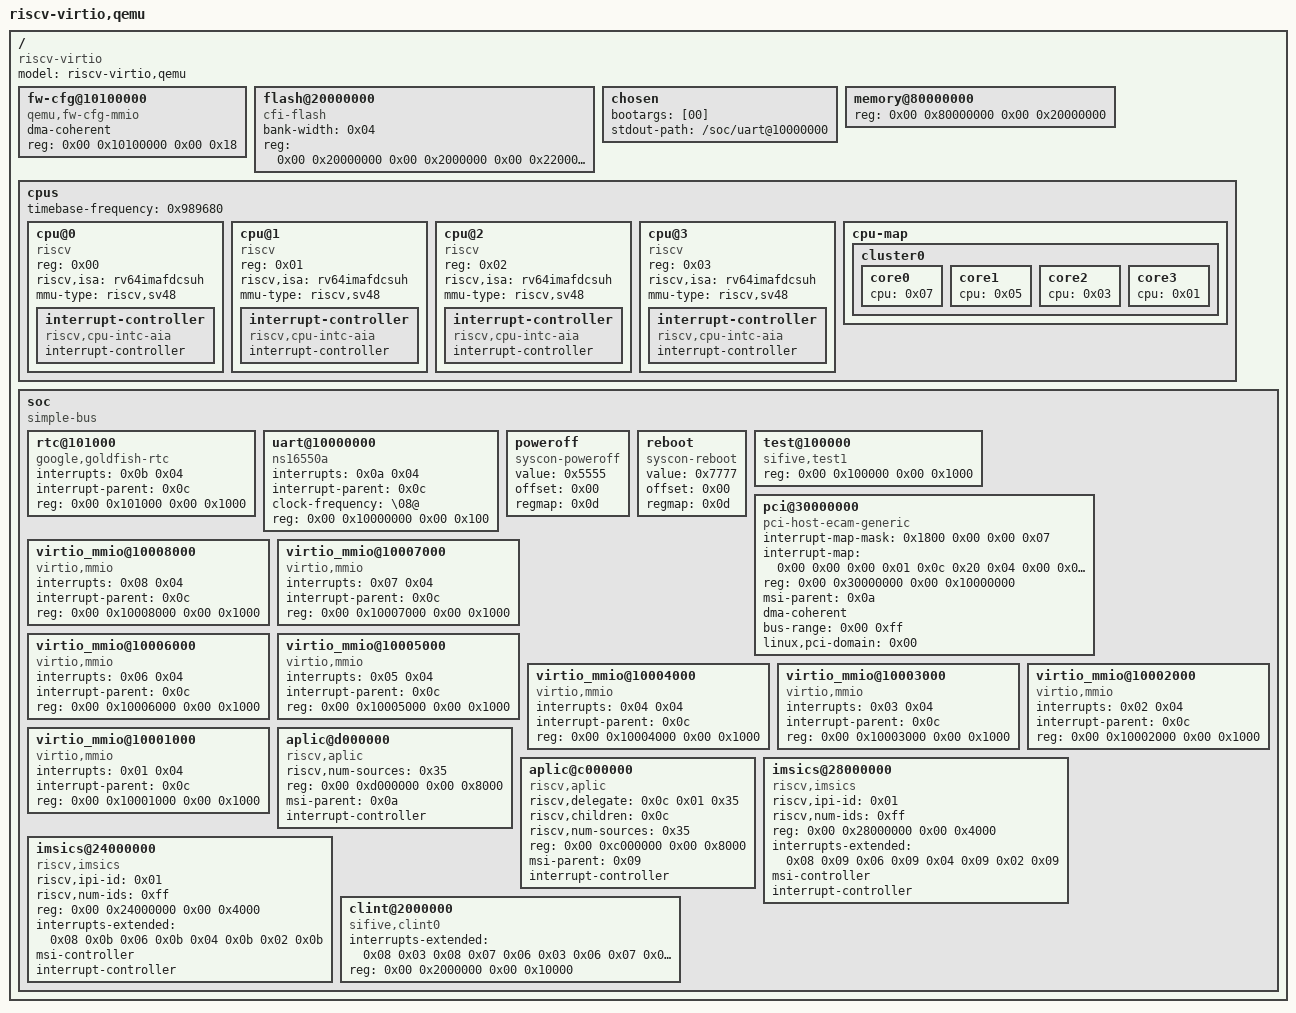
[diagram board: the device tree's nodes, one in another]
/dts-v1/;

/ {
	#address-cells = <0x02>;
	#size-cells = <0x02>;
	compatible = "riscv-virtio";
	model = "riscv-virtio,qemu";

	fw-cfg@10100000 {
		dma-coherent;
		reg = <0x00 0x10100000 0x00 0x18>;
		compatible = "qemu,fw-cfg-mmio";
	};

	flash@20000000 {
		bank-width = <0x04>;
		reg = <0x00 0x20000000 0x00 0x2000000 0x00 0x22000000 0x00 0x2000000>;
		compatible = "cfi-flash";
	};

	chosen {
		bootargs = [00];
		stdout-path = "/soc/uart@10000000";
	};

	memory@80000000 {
		device_type = "memory";
		reg = <0x00 0x80000000 0x00 0x20000000>;
	};

	cpus {
		#address-cells = <0x01>;
		#size-cells = <0x00>;
		timebase-frequency = <0x989680>;

		cpu@0 {
			phandle = <0x07>;
			device_type = "cpu";
			reg = <0x00>;
			status = "okay";
			compatible = "riscv";
			riscv,isa = "rv64imafdcsuh";
			mmu-type = "riscv,sv48";

			interrupt-controller {
				#interrupt-cells = <0x01>;
				interrupt-controller;
				compatible = "riscv,cpu-intc-aia\0riscv,cpu-intc";
				phandle = <0x08>;
			};
		};

		cpu@1 {
			phandle = <0x05>;
			device_type = "cpu";
			reg = <0x01>;
			status = "okay";
			compatible = "riscv";
			riscv,isa = "rv64imafdcsuh";
			mmu-type = "riscv,sv48";

			interrupt-controller {
				#interrupt-cells = <0x01>;
				interrupt-controller;
				compatible = "riscv,cpu-intc-aia\0riscv,cpu-intc";
				phandle = <0x06>;
			};
		};

		cpu@2 {
			phandle = <0x03>;
			device_type = "cpu";
			reg = <0x02>;
			status = "okay";
			compatible = "riscv";
			riscv,isa = "rv64imafdcsuh";
			mmu-type = "riscv,sv48";

			interrupt-controller {
				#interrupt-cells = <0x01>;
				interrupt-controller;
				compatible = "riscv,cpu-intc-aia\0riscv,cpu-intc";
				phandle = <0x04>;
			};
		};

		cpu@3 {
			phandle = <0x01>;
			device_type = "cpu";
			reg = <0x03>;
			status = "okay";
			compatible = "riscv";
			riscv,isa = "rv64imafdcsuh";
			mmu-type = "riscv,sv48";

			interrupt-controller {
				#interrupt-cells = <0x01>;
				interrupt-controller;
				compatible = "riscv,cpu-intc-aia\0riscv,cpu-intc";
				phandle = <0x02>;
			};
		};

		cpu-map {

			cluster0 {

				core0 {
					cpu = <0x07>;
				};

				core1 {
					cpu = <0x05>;
				};

				core2 {
					cpu = <0x03>;
				};

				core3 {
					cpu = <0x01>;
				};
			};
		};
	};

	soc {
		#address-cells = <0x02>;
		#size-cells = <0x02>;
		compatible = "simple-bus";
		ranges;

		rtc@101000 {
			interrupts = <0x0b 0x04>;
			interrupt-parent = <0x0c>;
			reg = <0x00 0x101000 0x00 0x1000>;
			compatible = "google,goldfish-rtc";
		};

		uart@10000000 {
			interrupts = <0x0a 0x04>;
			interrupt-parent = <0x0c>;
			clock-frequency = "\08@";
			reg = <0x00 0x10000000 0x00 0x100>;
			compatible = "ns16550a";
		};

		poweroff {
			value = <0x5555>;
			offset = <0x00>;
			regmap = <0x0d>;
			compatible = "syscon-poweroff";
		};

		reboot {
			value = <0x7777>;
			offset = <0x00>;
			regmap = <0x0d>;
			compatible = "syscon-reboot";
		};

		test@100000 {
			phandle = <0x0d>;
			reg = <0x00 0x100000 0x00 0x1000>;
			compatible = "sifive,test1\0sifive,test0\0syscon";
		};

		pci@30000000 {
			interrupt-map-mask = <0x1800 0x00 0x00 0x07>;
			interrupt-map = <0x00 0x00 0x00 0x01 0x0c 0x20 0x04 0x00 0x00 0x00 0x02 0x0c 0x21 0x04 0x00 0x00 0x00 0x03 0x0c 0x22 0x04 0x00 0x00 0x00 0x04 0x0c 0x23 0x04 0x800 0x00 0x00 0x01 0x0c 0x21 0x04 0x800 0x00 0x00 0x02 0x0c 0x22 0x04 0x800 0x00 0x00 0x03 0x0c 0x23 0x04 0x800 0x00 0x00 0x04 0x0c 0x20 0x04 0x1000 0x00 0x00 0x01 0x0c 0x22 0x04 0x1000 0x00 0x00 0x02 0x0c 0x23 0x04 0x1000 0x00 0x00 0x03 0x0c 0x20 0x04 0x1000 0x00 0x00 0x04 0x0c 0x21 0x04 0x1800 0x00 0x00 0x01 0x0c 0x23 0x04 0x1800 0x00 0x00 0x02 0x0c 0x20 0x04 0x1800 0x00 0x00 0x03 0x0c 0x21 0x04 0x1800 0x00 0x00 0x04 0x0c 0x22 0x04>;
			ranges = <0x1000000 0x00 0x00 0x00 0x3000000 0x00 0x10000 0x2000000 0x00 0x40000000 0x00 0x40000000 0x00 0x40000000 0x3000000 0x04 0x00 0x04 0x00 0x04 0x00>;
			reg = <0x00 0x30000000 0x00 0x10000000>;
			msi-parent = <0x0a>;
			dma-coherent;
			bus-range = <0x00 0xff>;
			linux,pci-domain = <0x00>;
			device_type = "pci";
			compatible = "pci-host-ecam-generic";
			#size-cells = <0x02>;
			#interrupt-cells = <0x01>;
			#address-cells = <0x03>;
		};

		virtio_mmio@10008000 {
			interrupts = <0x08 0x04>;
			interrupt-parent = <0x0c>;
			reg = <0x00 0x10008000 0x00 0x1000>;
			compatible = "virtio,mmio";
		};

		virtio_mmio@10007000 {
			interrupts = <0x07 0x04>;
			interrupt-parent = <0x0c>;
			reg = <0x00 0x10007000 0x00 0x1000>;
			compatible = "virtio,mmio";
		};

		virtio_mmio@10006000 {
			interrupts = <0x06 0x04>;
			interrupt-parent = <0x0c>;
			reg = <0x00 0x10006000 0x00 0x1000>;
			compatible = "virtio,mmio";
		};

		virtio_mmio@10005000 {
			interrupts = <0x05 0x04>;
			interrupt-parent = <0x0c>;
			reg = <0x00 0x10005000 0x00 0x1000>;
			compatible = "virtio,mmio";
		};

		virtio_mmio@10004000 {
			interrupts = <0x04 0x04>;
			interrupt-parent = <0x0c>;
			reg = <0x00 0x10004000 0x00 0x1000>;
			compatible = "virtio,mmio";
		};

		virtio_mmio@10003000 {
			interrupts = <0x03 0x04>;
			interrupt-parent = <0x0c>;
			reg = <0x00 0x10003000 0x00 0x1000>;
			compatible = "virtio,mmio";
		};

		virtio_mmio@10002000 {
			interrupts = <0x02 0x04>;
			interrupt-parent = <0x0c>;
			reg = <0x00 0x10002000 0x00 0x1000>;
			compatible = "virtio,mmio";
		};

		virtio_mmio@10001000 {
			interrupts = <0x01 0x04>;
			interrupt-parent = <0x0c>;
			reg = <0x00 0x10001000 0x00 0x1000>;
			compatible = "virtio,mmio";
		};

		aplic@d000000 {
			phandle = <0x0c>;
			riscv,num-sources = <0x35>;
			reg = <0x00 0xd000000 0x00 0x8000>;
			msi-parent = <0x0a>;
			interrupt-controller;
			#interrupt-cells = <0x02>;
			compatible = "riscv,aplic";
		};

		aplic@c000000 {
			phandle = <0x0b>;
			riscv,delegate = <0x0c 0x01 0x35>;
			riscv,children = <0x0c>;
			riscv,num-sources = <0x35>;
			reg = <0x00 0xc000000 0x00 0x8000>;
			msi-parent = <0x09>;
			interrupt-controller;
			#interrupt-cells = <0x02>;
			compatible = "riscv,aplic";
		};

		imsics@28000000 {
			phandle = <0x0a>;
			riscv,ipi-id = <0x01>;
			riscv,num-ids = <0xff>;
			reg = <0x00 0x28000000 0x00 0x4000>;
			interrupts-extended = <0x08 0x09 0x06 0x09 0x04 0x09 0x02 0x09>;
			msi-controller;
			interrupt-controller;
			#interrupt-cells = <0x00>;
			compatible = "riscv,imsics";
		};

		imsics@24000000 {
			phandle = <0x09>;
			riscv,ipi-id = <0x01>;
			riscv,num-ids = <0xff>;
			reg = <0x00 0x24000000 0x00 0x4000>;
			interrupts-extended = <0x08 0x0b 0x06 0x0b 0x04 0x0b 0x02 0x0b>;
			msi-controller;
			interrupt-controller;
			#interrupt-cells = <0x00>;
			compatible = "riscv,imsics";
		};

		clint@2000000 {
			interrupts-extended = <0x08 0x03 0x08 0x07 0x06 0x03 0x06 0x07 0x04 0x03 0x04 0x07 0x02 0x03 0x02 0x07>;
			reg = <0x00 0x2000000 0x00 0x10000>;
			compatible = "sifive,clint0\0riscv,clint0";
		};
	};
};
